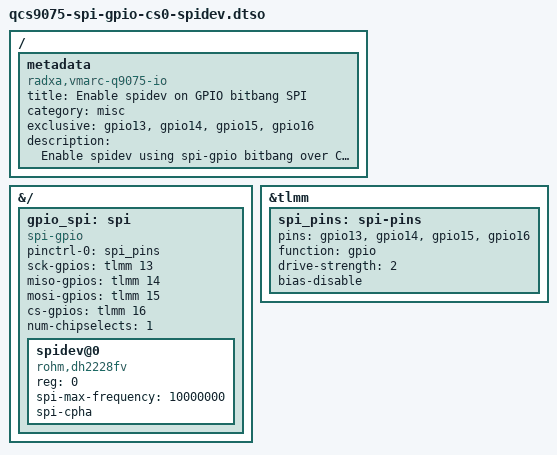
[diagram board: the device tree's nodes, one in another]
// SPDX-License-Identifier: BSD-3-Clause
/*
 * Copyright (c) 2026 Radxa Computer (Shenzhen) Co., Ltd.
 */

/dts-v1/;
/plugin/;

#include <dt-bindings/gpio/gpio.h>

/ {
    metadata {
        title = "Enable spidev on GPIO bitbang SPI";
        compatible = "radxa,vmarc-q9075-io";
        category = "misc";
        exclusive = "gpio13", "gpio14", "gpio15", "gpio16";
        description = "Enable spidev using spi-gpio bitbang over CS0.";
    };
};

&{/} {
    gpio_spi: spi {
        compatible = "spi-gpio";
        pinctrl-names = "default";
        pinctrl-0 = <&spi_pins>;
        #address-cells = <1>;
        #size-cells = <0>;

        sck-gpios  = <&tlmm 13 GPIO_ACTIVE_HIGH>;
        miso-gpios = <&tlmm 14 GPIO_ACTIVE_HIGH>;
        mosi-gpios = <&tlmm 15 GPIO_ACTIVE_HIGH>;
        cs-gpios = <&tlmm 16 GPIO_ACTIVE_HIGH>;
        num-chipselects = <1>;

        spidev@0 {
            compatible = "rohm,dh2228fv";
            reg = <0>;
            spi-max-frequency = <10000000>;
            spi-cpha;
        };
    };
};

&tlmm {
    spi_pins: spi-pins {
        pins = "gpio13", "gpio14", "gpio15", "gpio16";
        function = "gpio";
        drive-strength = <2>;
        bias-disable;
    };
};
